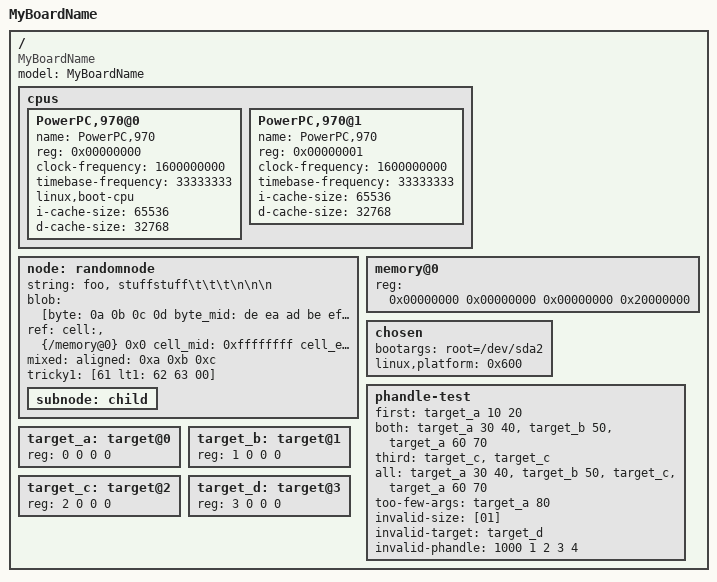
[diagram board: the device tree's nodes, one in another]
/dts-v1/;

/memreserve/ 0x1000000000000000 0x0000000002000000;
memrsv2: /memreserve/ 0x2000000000000000 0x0100000000000000;
/memreserve/ 0x0000000000000000 0x0000000000000014;

/ {
	model = "MyBoardName";
	compatible = "MyBoardName", "MyBoardFamilyName";
	#address-cells = <2>;
	#size-cells = <2>;

	cpus {
		linux,phandle = <0x1>;
		#address-cells = <1>;
		#size-cells = <0>;
		PowerPC,970@0 {
			name = "PowerPC,970";
			device_type = "cpu";
			reg = <0x00000000>;
			clock-frequency = <1600000000>;
			timebase-frequency = <33333333>;
			linux,boot-cpu;
			i-cache-size = <65536>;
			d-cache-size = <32768>;
		};

		PowerPC,970@1 {
			name = "PowerPC,970";
			device_type = "cpu";
			reg = <0x00000001>;
			clock-frequency = <1600000000>;
			timebase-frequency = <33333333>;
			i-cache-size = <65536>;
			d-cache-size = <32768>;
		};

	};

	node: randomnode {
		prop: string = str: "foo", str_mid: "stuffstuff\t\t\t\n\n\n" str_end: ;
		blob = [byte: 0a 0b 0c 0d byte_mid: de ea ad be ef byte_end: ];
		ref = < cell: &{/memory@0} 0x0 cell_mid: 0xffffffff cell_end: >;
		mixed = "abc", pre: [1234] post: , gap: < aligned: 0xa 0xb 0xc>;
		tricky1 = [61 lt1: 62 63 00];
		subnode: child {
		};
		/* subnode_end: is auto-generated by node emit */
	};
	/* node_end: is auto-generated by node emit */

	memory@0 {
		device_type = "memory";
		memreg: reg = <0x00000000 0x00000000 0x00000000 0x20000000>;
	};

	chosen {
		bootargs = "root=/dev/sda2";
		linux,platform = <0x600>;
	};

	phandle-test {
		first = <&target_a 10 20>;
		both = <&target_a 30 40 &target_b 50 &target_a 60 70>;
		third = <&target_c &target_c>;
		all = <&target_a 30 40 &target_b 50 &target_c &target_a 60 70>;
		too-few-args = <&target_a 80>;
		invalid-size = [01];
		invalid-target = <&target_d>;
		invalid-phandle = <1000 1 2 3 4>;
	};

	target_a: target@0 {
		reg = <0 0 0 0>;
		#gpio-cells = <2>;
	};

	target_b: target@1 {
		reg = <1 0 0 0>;
		#gpio-cells = <1>;
	};

	target_c: target@2 {
		reg = <2 0 0 0>;
		#gpio-cells = <0>;
	};

	target_d: target@3 {
		reg = <3 0 0 0>;
		#gpio-cells = [01];	/* invalid cell value */
	};

};

